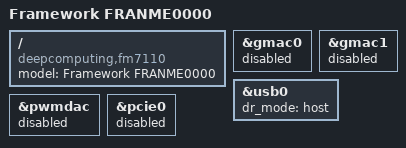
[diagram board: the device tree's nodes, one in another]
// SPDX-License-Identifier: GPL-2.0 OR MIT
/*
 * Copyright (C) 2022 StarFive Technology Co., Ltd.
 * Copyright (C) 2022 Emil Renner Berthing <kernel@esmil.dk>
 */

/dts-v1/;
#include "jh7110-common.dtsi"

/ {
	model = "Framework FRANME0000";
	compatible = "deepcomputing,fm7110", "starfive,jh7110";
};

&gmac0 {
	status = "disabled";
};

&gmac1 {
	status = "disabled";
};

&usb0 {
	dr_mode = "host";
	status = "okay";
};

&pwmdac {
	status = "disabled";
};

&pcie0 {
	status = "disabled";
};
